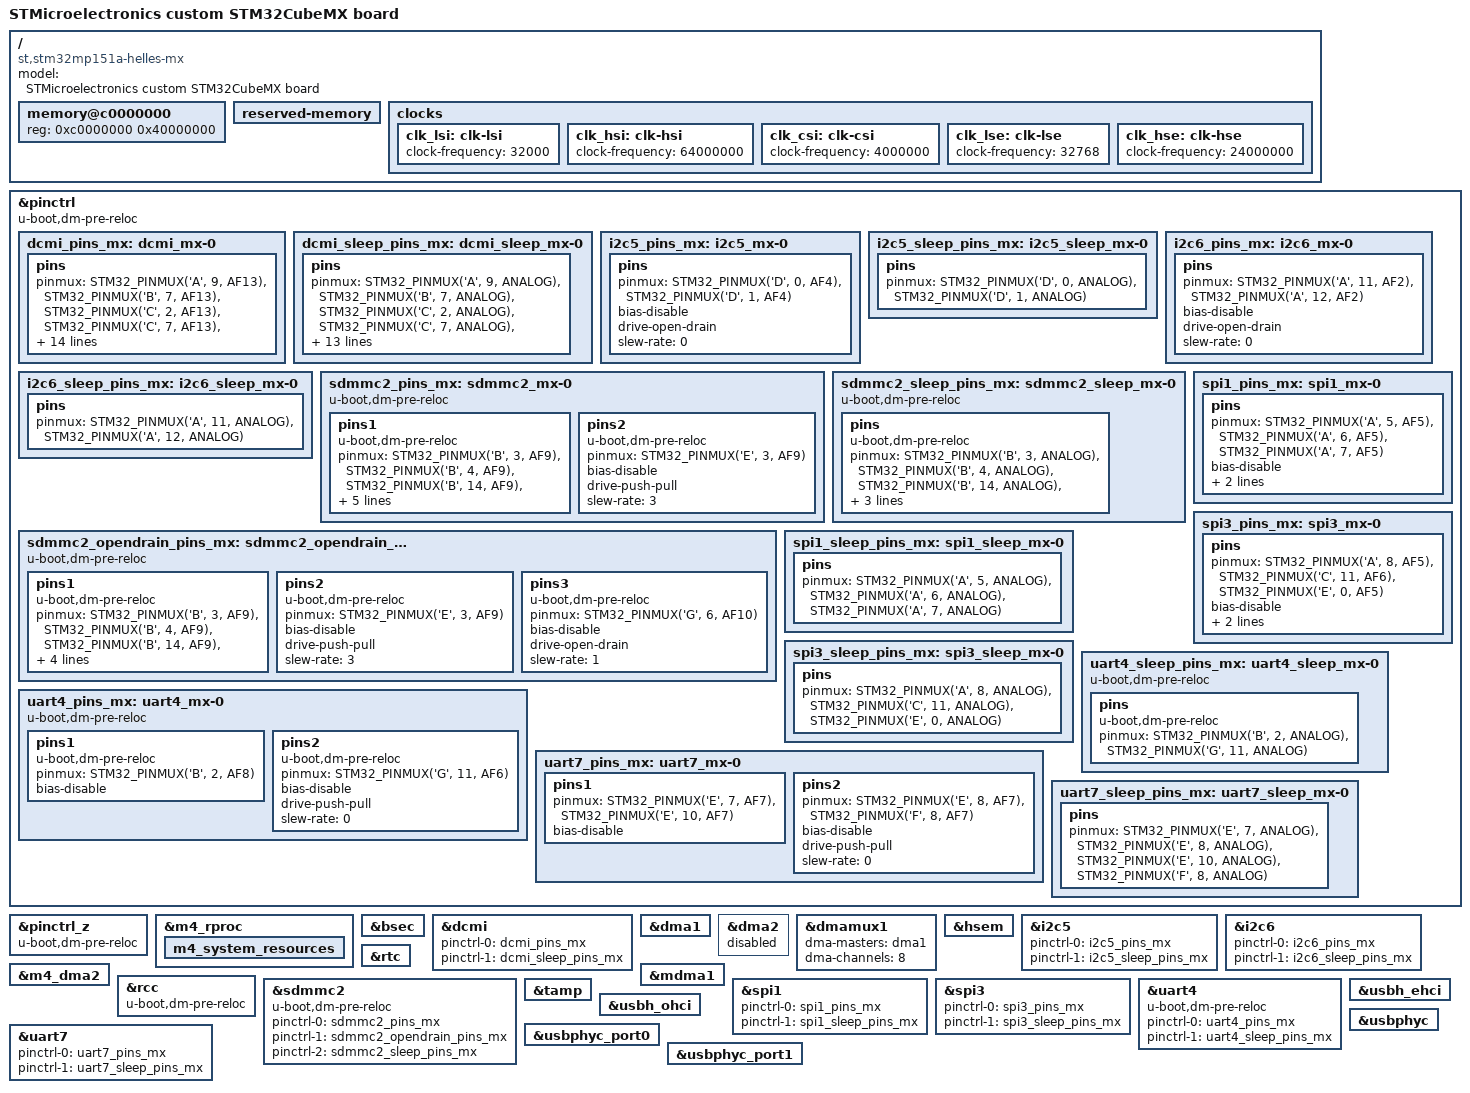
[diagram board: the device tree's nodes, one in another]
/* SPDX-License-Identifier: (GPL-2.0+ OR BSD-3-Clause) */
/*
 * Copyright (C) STMicroelectronics 2020 - All Rights Reserved
 * Author: STM32CubeMX code generation for STMicroelectronics.
 */

/* For more information on Device Tree configuration, please refer to
 * https://wiki.st.com/stm32mpu/wiki/Category:Device_tree_configuration
 */

/dts-v1/;
#include <dt-bindings/pinctrl/stm32-pinfunc.h>

#include "stm32mp151.dtsi"
#include "stm32mp15xa.dtsi"
#include "stm32mp15xxab-pinctrl.dtsi"
#include "stm32mp157-m4-srm.dtsi"

/* USER CODE BEGIN includes */
/* USER CODE END includes */

/ {
	model = "STMicroelectronics custom STM32CubeMX board";
	compatible = "st,stm32mp151a-helles-mx", "st,stm32mp151";

	memory@c0000000 {
		device_type = "memory";
		reg = <0xc0000000 0x40000000>;

		/* USER CODE BEGIN memory */
		/* USER CODE END memory */
	};

	reserved-memory {
		#address-cells = <1>;
		#size-cells = <1>;
		ranges;

		/* USER CODE BEGIN reserved-memory */
		/* USER CODE END reserved-memory */
	};

	/* USER CODE BEGIN root */
	/* USER CODE END root */

	clocks {

		/* USER CODE BEGIN clocks */
		/* USER CODE END clocks */

#ifndef CONFIG_STM32MP1_TRUSTED
		clk_lsi: clk-lsi {
			clock-frequency = <32000>;
		};
		clk_hsi: clk-hsi {
			clock-frequency = <64000000>;
		};
		clk_csi: clk-csi {
			clock-frequency = <4000000>;
		};
		clk_lse: clk-lse {
			clock-frequency = <32768>;
		};
		clk_hse: clk-hse {
			clock-frequency = <24000000>;
		};
#endif	/*CONFIG_STM32MP1_TRUSTED*/
	};

}; /*root*/

&pinctrl {
	u-boot,dm-pre-reloc;

	dcmi_pins_mx: dcmi_mx-0 {
		pins {
			pinmux = <STM32_PINMUX('A', 9, AF13)>, /* DCMI_D0 */
					 <STM32_PINMUX('B', 7, AF13)>, /* DCMI_VSYNC */
					 <STM32_PINMUX('C', 2, AF13)>, /* DCMI_PIXCLK */
					 <STM32_PINMUX('C', 7, AF13)>, /* DCMI_D1 */
					 <STM32_PINMUX('C', 8, AF13)>, /* DCMI_D2 */
					 <STM32_PINMUX('C', 10, AF13)>, /* DCMI_D8 */
					 <STM32_PINMUX('C', 12, AF13)>, /* DCMI_D9 */
					 <STM32_PINMUX('D', 2, AF13)>, /* DCMI_D11 */
					 <STM32_PINMUX('D', 3, AF13)>, /* DCMI_D5 */
					 <STM32_PINMUX('D', 6, AF13)>, /* DCMI_D10 */
					 <STM32_PINMUX('D', 9, AF13)>, /* DCMI_HSYNC */
					 <STM32_PINMUX('E', 1, AF13)>, /* DCMI_D3 */
					 <STM32_PINMUX('E', 4, AF13)>, /* DCMI_D4 */
					 <STM32_PINMUX('E', 5, AF13)>, /* DCMI_D6 */
					 <STM32_PINMUX('E', 6, AF13)>, /* DCMI_D7 */
					 <STM32_PINMUX('F', 11, AF13)>, /* DCMI_D12 */
					 <STM32_PINMUX('G', 15, AF13)>; /* DCMI_D13 */
			bias-disable;
		};
	};

	dcmi_sleep_pins_mx: dcmi_sleep_mx-0 {
		pins {
			pinmux = <STM32_PINMUX('A', 9, ANALOG)>, /* DCMI_D0 */
					 <STM32_PINMUX('B', 7, ANALOG)>, /* DCMI_VSYNC */
					 <STM32_PINMUX('C', 2, ANALOG)>, /* DCMI_PIXCLK */
					 <STM32_PINMUX('C', 7, ANALOG)>, /* DCMI_D1 */
					 <STM32_PINMUX('C', 8, ANALOG)>, /* DCMI_D2 */
					 <STM32_PINMUX('C', 10, ANALOG)>, /* DCMI_D8 */
					 <STM32_PINMUX('C', 12, ANALOG)>, /* DCMI_D9 */
					 <STM32_PINMUX('D', 2, ANALOG)>, /* DCMI_D11 */
					 <STM32_PINMUX('D', 3, ANALOG)>, /* DCMI_D5 */
					 <STM32_PINMUX('D', 6, ANALOG)>, /* DCMI_D10 */
					 <STM32_PINMUX('D', 9, ANALOG)>, /* DCMI_HSYNC */
					 <STM32_PINMUX('E', 1, ANALOG)>, /* DCMI_D3 */
					 <STM32_PINMUX('E', 4, ANALOG)>, /* DCMI_D4 */
					 <STM32_PINMUX('E', 5, ANALOG)>, /* DCMI_D6 */
					 <STM32_PINMUX('E', 6, ANALOG)>, /* DCMI_D7 */
					 <STM32_PINMUX('F', 11, ANALOG)>, /* DCMI_D12 */
					 <STM32_PINMUX('G', 15, ANALOG)>; /* DCMI_D13 */
		};
	};

	i2c5_pins_mx: i2c5_mx-0 {
		pins {
			pinmux = <STM32_PINMUX('D', 0, AF4)>, /* I2C5_SDA */
					 <STM32_PINMUX('D', 1, AF4)>; /* I2C5_SCL */
			bias-disable;
			drive-open-drain;
			slew-rate = <0>;
		};
	};

	i2c5_sleep_pins_mx: i2c5_sleep_mx-0 {
		pins {
			pinmux = <STM32_PINMUX('D', 0, ANALOG)>, /* I2C5_SDA */
					 <STM32_PINMUX('D', 1, ANALOG)>; /* I2C5_SCL */
		};
	};

	i2c6_pins_mx: i2c6_mx-0 {
		pins {
			pinmux = <STM32_PINMUX('A', 11, AF2)>, /* I2C6_SCL */
					 <STM32_PINMUX('A', 12, AF2)>; /* I2C6_SDA */
			bias-disable;
			drive-open-drain;
			slew-rate = <0>;
		};
	};

	i2c6_sleep_pins_mx: i2c6_sleep_mx-0 {
		pins {
			pinmux = <STM32_PINMUX('A', 11, ANALOG)>, /* I2C6_SCL */
					 <STM32_PINMUX('A', 12, ANALOG)>; /* I2C6_SDA */
		};
	};

	sdmmc2_pins_mx: sdmmc2_mx-0 {
		u-boot,dm-pre-reloc;
		pins1 {
			u-boot,dm-pre-reloc;
			pinmux = <STM32_PINMUX('B', 3, AF9)>, /* SDMMC2_D2 */
					 <STM32_PINMUX('B', 4, AF9)>, /* SDMMC2_D3 */
					 <STM32_PINMUX('B', 14, AF9)>, /* SDMMC2_D0 */
					 <STM32_PINMUX('B', 15, AF9)>, /* SDMMC2_D1 */
					 <STM32_PINMUX('G', 6, AF10)>; /* SDMMC2_CMD */
			bias-disable;
			drive-push-pull;
			slew-rate = <1>;
		};
		pins2 {
			u-boot,dm-pre-reloc;
			pinmux = <STM32_PINMUX('E', 3, AF9)>; /* SDMMC2_CK */
			bias-disable;
			drive-push-pull;
			slew-rate = <3>;
		};
	};

	sdmmc2_opendrain_pins_mx: sdmmc2_opendrain_mx-0 {
		u-boot,dm-pre-reloc;
		pins1 {
			u-boot,dm-pre-reloc;
			pinmux = <STM32_PINMUX('B', 3, AF9)>, /* SDMMC2_D2 */
					 <STM32_PINMUX('B', 4, AF9)>, /* SDMMC2_D3 */
					 <STM32_PINMUX('B', 14, AF9)>, /* SDMMC2_D0 */
					 <STM32_PINMUX('B', 15, AF9)>; /* SDMMC2_D1 */
			bias-disable;
			drive-push-pull;
			slew-rate = <1>;
		};
		pins2 {
			u-boot,dm-pre-reloc;
			pinmux = <STM32_PINMUX('E', 3, AF9)>; /* SDMMC2_CK */
			bias-disable;
			drive-push-pull;
			slew-rate = <3>;
		};
		pins3 {
			u-boot,dm-pre-reloc;
			pinmux = <STM32_PINMUX('G', 6, AF10)>; /* SDMMC2_CMD */
			bias-disable;
			drive-open-drain;
			slew-rate = <1>;
		};
	};

	sdmmc2_sleep_pins_mx: sdmmc2_sleep_mx-0 {
		u-boot,dm-pre-reloc;
		pins {
			u-boot,dm-pre-reloc;
			pinmux = <STM32_PINMUX('B', 3, ANALOG)>, /* SDMMC2_D2 */
					 <STM32_PINMUX('B', 4, ANALOG)>, /* SDMMC2_D3 */
					 <STM32_PINMUX('B', 14, ANALOG)>, /* SDMMC2_D0 */
					 <STM32_PINMUX('B', 15, ANALOG)>, /* SDMMC2_D1 */
					 <STM32_PINMUX('E', 3, ANALOG)>, /* SDMMC2_CK */
					 <STM32_PINMUX('G', 6, ANALOG)>; /* SDMMC2_CMD */
		};
	};

	spi1_pins_mx: spi1_mx-0 {
		pins {
			pinmux = <STM32_PINMUX('A', 5, AF5)>, /* SPI1_SCK */
					 <STM32_PINMUX('A', 6, AF5)>, /* SPI1_MISO */
					 <STM32_PINMUX('A', 7, AF5)>; /* SPI1_MOSI */
			bias-disable;
			drive-push-pull;
			slew-rate = <1>;
		};
	};

	spi1_sleep_pins_mx: spi1_sleep_mx-0 {
		pins {
			pinmux = <STM32_PINMUX('A', 5, ANALOG)>, /* SPI1_SCK */
					 <STM32_PINMUX('A', 6, ANALOG)>, /* SPI1_MISO */
					 <STM32_PINMUX('A', 7, ANALOG)>; /* SPI1_MOSI */
		};
	};

	spi3_pins_mx: spi3_mx-0 {
		pins {
			pinmux = <STM32_PINMUX('A', 8, AF5)>, /* SPI3_MOSI */
					 <STM32_PINMUX('C', 11, AF6)>, /* SPI3_MISO */
					 <STM32_PINMUX('E', 0, AF5)>; /* SPI3_SCK */
			bias-disable;
			drive-push-pull;
			slew-rate = <1>;
		};
	};

	spi3_sleep_pins_mx: spi3_sleep_mx-0 {
		pins {
			pinmux = <STM32_PINMUX('A', 8, ANALOG)>, /* SPI3_MOSI */
					 <STM32_PINMUX('C', 11, ANALOG)>, /* SPI3_MISO */
					 <STM32_PINMUX('E', 0, ANALOG)>; /* SPI3_SCK */
		};
	};

	uart4_pins_mx: uart4_mx-0 {
		u-boot,dm-pre-reloc;
		pins1 {
			u-boot,dm-pre-reloc;
			pinmux = <STM32_PINMUX('B', 2, AF8)>; /* UART4_RX */
			bias-disable;
		};
		pins2 {
			u-boot,dm-pre-reloc;
			pinmux = <STM32_PINMUX('G', 11, AF6)>; /* UART4_TX */
			bias-disable;
			drive-push-pull;
			slew-rate = <0>;
		};
	};

	uart4_sleep_pins_mx: uart4_sleep_mx-0 {
		u-boot,dm-pre-reloc;
		pins {
			u-boot,dm-pre-reloc;
			pinmux = <STM32_PINMUX('B', 2, ANALOG)>, /* UART4_RX */
					 <STM32_PINMUX('G', 11, ANALOG)>; /* UART4_TX */
		};
	};

	uart7_pins_mx: uart7_mx-0 {
		pins1 {
			pinmux = <STM32_PINMUX('E', 7, AF7)>, /* UART7_RX */
					 <STM32_PINMUX('E', 10, AF7)>; /* UART7_CTS */
			bias-disable;
		};
		pins2 {
			pinmux = <STM32_PINMUX('E', 8, AF7)>, /* UART7_TX */
					 <STM32_PINMUX('F', 8, AF7)>; /* UART7_RTS */
			bias-disable;
			drive-push-pull;
			slew-rate = <0>;
		};
	};

	uart7_sleep_pins_mx: uart7_sleep_mx-0 {
		pins {
			pinmux = <STM32_PINMUX('E', 7, ANALOG)>, /* UART7_RX */
					 <STM32_PINMUX('E', 8, ANALOG)>, /* UART7_TX */
					 <STM32_PINMUX('E', 10, ANALOG)>, /* UART7_CTS */
					 <STM32_PINMUX('F', 8, ANALOG)>; /* UART7_RTS */
		};
	};

	/* USER CODE BEGIN pinctrl */
	/* USER CODE END pinctrl */
};

&pinctrl_z {
	u-boot,dm-pre-reloc;

	/* USER CODE BEGIN pinctrl_z */
	/* USER CODE END pinctrl_z */
};

&m4_rproc{
	status = "okay";

	/* USER CODE BEGIN m4_rproc */
	/* USER CODE END m4_rproc */

	m4_system_resources{
		status = "okay";

		/* USER CODE BEGIN m4_system_resources */
		/* USER CODE END m4_system_resources */
	};
};

&bsec{
	status = "okay";

	/* USER CODE BEGIN bsec */
	/* USER CODE END bsec */
};

&dcmi{
	pinctrl-names = "default", "sleep";
	pinctrl-0 = <&dcmi_pins_mx>;
	pinctrl-1 = <&dcmi_sleep_pins_mx>;
	status = "okay";

	/* USER CODE BEGIN dcmi */
	/* USER CODE END dcmi */
};

&dma1{
	status = "okay";

	/* USER CODE BEGIN dma1 */
	/* USER CODE END dma1 */
};

&dma2{
	status = "disabled";

	/* USER CODE BEGIN dma2 */
	/* USER CODE END dma2 */
};

&dmamux1{

	dma-masters = <&dma1>;
	dma-channels = <8>;

	status = "okay";

	/* USER CODE BEGIN dmamux1 */
	/* USER CODE END dmamux1 */
};

&hsem{
	status = "okay";

	/* USER CODE BEGIN hsem */
	/* USER CODE END hsem */
};

&i2c5{
	pinctrl-names = "default", "sleep";
	pinctrl-0 = <&i2c5_pins_mx>;
	pinctrl-1 = <&i2c5_sleep_pins_mx>;
	status = "okay";

	/* USER CODE BEGIN i2c5 */
	/* USER CODE END i2c5 */
};

&i2c6{
	pinctrl-names = "default", "sleep";
	pinctrl-0 = <&i2c6_pins_mx>;
	pinctrl-1 = <&i2c6_sleep_pins_mx>;
	status = "okay";

	/* USER CODE BEGIN i2c6 */
	/* USER CODE END i2c6 */
};

&m4_dma2{
	status = "okay";

	/* USER CODE BEGIN m4_dma2 */
	/* USER CODE END m4_dma2 */
};

&mdma1{
	status = "okay";

	/* USER CODE BEGIN mdma1 */
	/* USER CODE END mdma1 */
};

&rcc{
	u-boot,dm-pre-reloc;
	status = "okay";

	/* USER CODE BEGIN rcc */
	/* USER CODE END rcc */
};

&rtc{
	status = "okay";

	/* USER CODE BEGIN rtc */
	/* USER CODE END rtc */
};

&sdmmc2{
	u-boot,dm-pre-reloc;
	pinctrl-names = "default", "opendrain", "sleep";
	pinctrl-0 = <&sdmmc2_pins_mx>;
	pinctrl-1 = <&sdmmc2_opendrain_pins_mx>;
	pinctrl-2 = <&sdmmc2_sleep_pins_mx>;
	status = "okay";

	/* USER CODE BEGIN sdmmc2 */
	/* USER CODE END sdmmc2 */
};

&spi1{
	pinctrl-names = "default", "sleep";
	pinctrl-0 = <&spi1_pins_mx>;
	pinctrl-1 = <&spi1_sleep_pins_mx>;
	status = "okay";

	/* USER CODE BEGIN spi1 */
	/* USER CODE END spi1 */
};

&spi3{
	pinctrl-names = "default", "sleep";
	pinctrl-0 = <&spi3_pins_mx>;
	pinctrl-1 = <&spi3_sleep_pins_mx>;
	status = "okay";

	/* USER CODE BEGIN spi3 */
	/* USER CODE END spi3 */
};

&tamp{
	status = "okay";

	/* USER CODE BEGIN tamp */
	/* USER CODE END tamp */
};

&uart4{
	u-boot,dm-pre-reloc;
	pinctrl-names = "default", "sleep";
	pinctrl-0 = <&uart4_pins_mx>;
	pinctrl-1 = <&uart4_sleep_pins_mx>;
	status = "okay";

	/* USER CODE BEGIN uart4 */
	/* USER CODE END uart4 */
};

&uart7{
	pinctrl-names = "default", "sleep";
	pinctrl-0 = <&uart7_pins_mx>;
	pinctrl-1 = <&uart7_sleep_pins_mx>;
	status = "okay";

	/* USER CODE BEGIN uart7 */
	/* USER CODE END uart7 */
};

&usbh_ehci{
	status = "okay";

	/* USER CODE BEGIN usbh_ehci */
	/* USER CODE END usbh_ehci */
};

&usbh_ohci{
	status = "okay";

	/* USER CODE BEGIN usbh_ohci */
	/* USER CODE END usbh_ohci */
};

&usbphyc{
	status = "okay";

	/* USER CODE BEGIN usbphyc */
	/* USER CODE END usbphyc */
};

&usbphyc_port0{
	status = "okay";

	/* USER CODE BEGIN usbphyc_port0 */
	/* USER CODE END usbphyc_port0 */
};

&usbphyc_port1{
	status = "okay";

	/* USER CODE BEGIN usbphyc_port1 */
	/* USER CODE END usbphyc_port1 */
};

/* USER CODE BEGIN addons */
/* USER CODE END addons */

